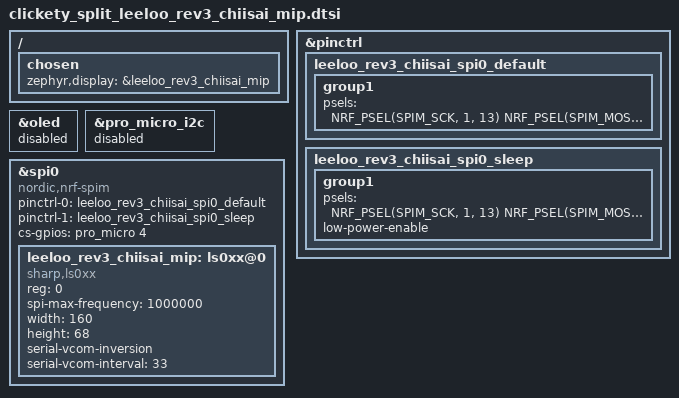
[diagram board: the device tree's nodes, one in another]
/*
 * Copyright (c) 2026 Clickety Split Ltd.
 * SPDX-License-Identifier: MIT
 */

#include <dt-bindings/gpio/gpio.h>
#include <zephyr/dt-bindings/pinctrl/nrf-pinctrl.h>

/ {
    chosen {
        zephyr,display = &leeloo_rev3_chiisai_mip;
    };
};

&pinctrl {
    leeloo_rev3_chiisai_spi0_default:
        leeloo_rev3_chiisai_spi0_default {
        group1 {
            /*
             * Leeloo rev3 display connector:
             *
             *   Pro Micro D3 / SCK  -> Chiisai P1.13
             *   Pro Micro D2 / MOSI -> Chiisai P1.12
             */
            psels = <
                NRF_PSEL(SPIM_SCK, 1, 13)
                NRF_PSEL(SPIM_MOSI, 1, 12)
            >;
        };
    };

    leeloo_rev3_chiisai_spi0_sleep:
        leeloo_rev3_chiisai_spi0_sleep {
        group1 {
            psels = <
                NRF_PSEL(SPIM_SCK, 1, 13)
                NRF_PSEL(SPIM_MOSI, 1, 12)
            >;
            low-power-enable;
        };
    };
};

/*
 * The Leeloo base definition retains its historical SSD1306 OLED on
 * pro_micro_i2c for rev1 compatibility. The rev2 Chiisai integration uses
 * that peripheral as SPI0 for the MIP LCD, so both the inherited
 * OLED child and I2C0 bus must be disabled.
 */
&oled {
    status = "disabled";
};

&pro_micro_i2c {
    status = "disabled";
};

&spi0 {
    compatible = "nordic,nrf-spim";
    status = "okay";

    pinctrl-0 = <&leeloo_rev3_chiisai_spi0_default>;
    pinctrl-1 = <&leeloo_rev3_chiisai_spi0_sleep>;
    pinctrl-names = "default", "sleep";

    cs-gpios = <&pro_micro 4 GPIO_ACTIVE_HIGH>;

    leeloo_rev3_chiisai_mip: ls0xx@0 {
        compatible = "sharp,ls0xx";
        status = "okay";

        reg = <0>;
        spi-max-frequency = <1000000>;

        width = <160>;
        height = <68>;

        serial-vcom-inversion;
        serial-vcom-interval = <33>;
    };
};
